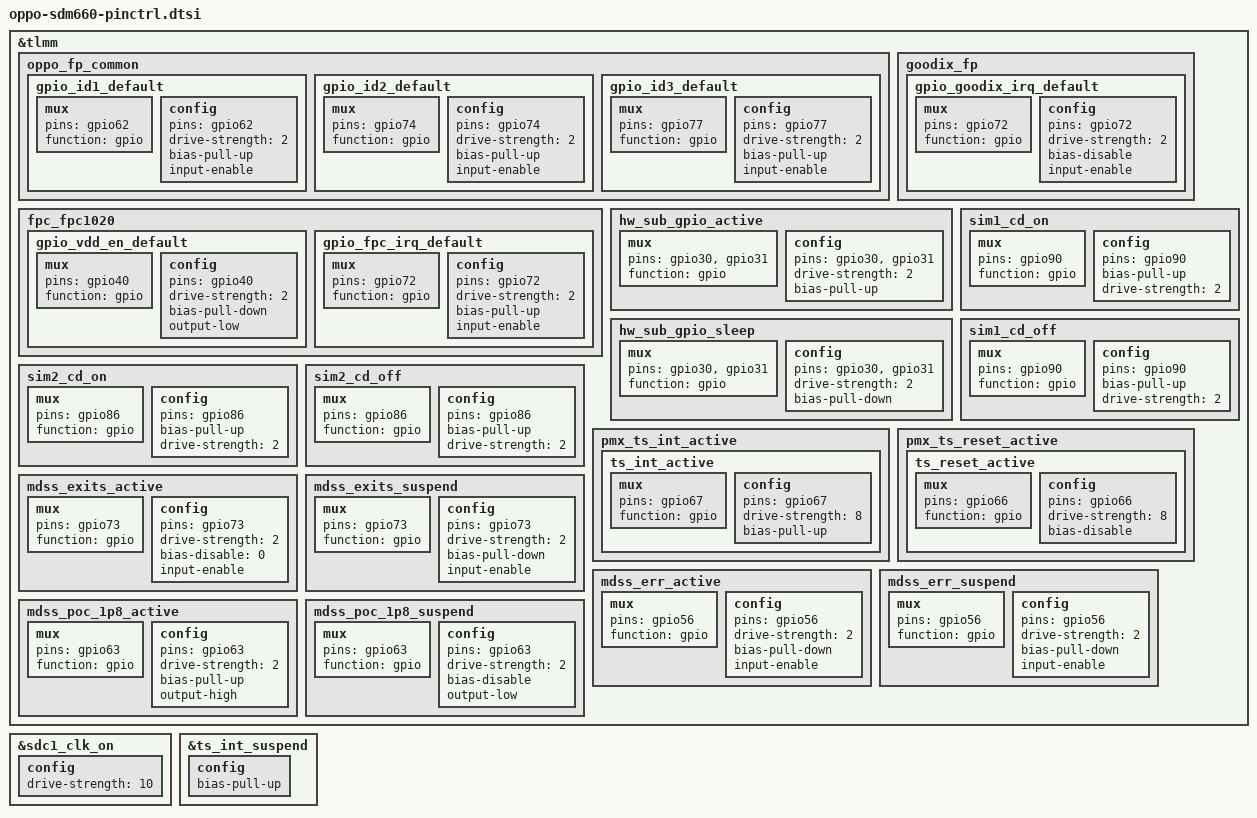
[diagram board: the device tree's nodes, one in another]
/* Copyright shits here */

&tlmm {
	oppo_fp_common {
		gpio_id1_default: gpio_id1_default {
			mux {
				pins = "gpio62";
				function = "gpio";
			};
			config {
				pins = "gpio62";
				drive-strength = <2>;
				bias-pull-up;
				input-enable;
			};
		};

		gpio_id2_default: gpio_id2_default {
			mux {
				pins = "gpio74";
				function = "gpio";
			};
			config {
				pins = "gpio74";
				drive-strength = <2>;
				bias-pull-up;
				input-enable;
			};
		};

		gpio_id3_default: gpio_id3_default {
			mux {
				pins = "gpio77";
				function = "gpio";
			};
			config {
				pins = "gpio77";
				drive-strength = <2>;
				bias-pull-up;
				input-enable;
			};
		};
	};

	fpc_fpc1020 {
		gpio_vdd_en_default: gpio_vdd_en_default {
			mux {
				pins = "gpio40";
				function = "gpio";
			};
			config {
				pins = "gpio40";
				drive-strength = <2>;
				bias-pull-down;
				output-low;
			};
		};

		gpio_fpc_irq_default: gpio_fpc_irq_default {
			mux {
				pins = "gpio72";
				function = "gpio";
			};
			config {
				pins = "gpio72";
				drive-strength = <2>;
				bias-pull-up;
				input-enable;
			};
		};
	};

	goodix_fp {
		gpio_goodix_irq_default: gpio_goodix_irq_default {
			mux {
				pins = "gpio72";
				function = "gpio";
			};
			config {
				pins = "gpio72";
				drive-strength = <2>;
				bias-disable;
				input-enable;
			};
		};
	};

	/* active state */
	hw_sub_gpio_active: hw_sub_gpio_active {
		mux {
			pins = "gpio30", "gpio31";
			function = "gpio";
		};
		config {
			pins = "gpio30", "gpio31";
			drive-strength = <2>; /* 2 MA */
			bias-pull-up;
		};
	};

	/* sleep state */
	hw_sub_gpio_sleep: hw_sub_gpio_sleep {
		mux {
			pins = "gpio30", "gpio31";
			function = "gpio";
		};
		config {
			pins = "gpio30", "gpio31";
			drive-strength = <2>; /* 2 MA */
			bias-pull-down; /* PULL DOWN */
		};
	};

	sim1_cd_on: sim1_cd_on {
		mux {
			pins = "gpio90";
			function = "gpio";
		};
		config {
			pins = "gpio90";
			bias-pull-up; /* pull up */
			drive-strength = <2>; /* 2 MA */
		};
	};

	sim1_cd_off: sim1_cd_off {
		mux {
			pins = "gpio90";
			function = "gpio";
		};
		config {
			pins = "gpio90";
			bias-pull-up; /* pull up */
			drive-strength = <2>; /* 2 MA */
		};
	};
	
	sim2_cd_on: sim2_cd_on {
		mux {
			pins = "gpio86";
			function = "gpio";
		};
		config {
			pins = "gpio86";
			bias-pull-up; /* pull up */
			drive-strength = <2>; /* 2 MA */
		};
	};

	sim2_cd_off: sim2_cd_off {
		mux {
			pins = "gpio86";
			function = "gpio";
		};
		config {
			pins = "gpio86";
			bias-pull-up; /* pull up */
			drive-strength = <2>; /* 2 MA */
		};
	};

	pmx_ts_int_active {
		ts_int_active: ts_int_active {
			mux {
				pins = "gpio67";
				function = "gpio";
			};
			config {
				pins = "gpio67";
				drive-strength = <8>;
				bias-pull-up;
			};
		};
	};

	pmx_ts_reset_active {
		ts_reset_active: ts_reset_active {
			mux {
				pins = "gpio66";
				function = "gpio";
			};
			config {
				pins = "gpio66";
				drive-strength = <8>;
				bias-disable;
			};
		};
	};

	mdss_exits_active: mdss_exits_active {
		mux {
			pins = "gpio73";
			function = "gpio";
		};
		config {
			pins = "gpio73";
			drive-strength = <2>; /* 2 mA */
			bias-disable = <0>; /* no pull */
			input-enable;
		};
	};

	mdss_exits_suspend: mdss_exits_suspend {
		mux {
			pins = "gpio73";
			function = "gpio";
		};
		config {
			pins = "gpio73";
			drive-strength = <2>; /* 2 mA */
			bias-pull-down; /* pull down */
			input-enable;
		};
	};

	mdss_err_active: mdss_err_active {
		mux {
			pins = "gpio56";
			function = "gpio";
		};
		config {
			pins = "gpio56";
			drive-strength = <2>; /* 2 mA */
			bias-pull-down; /* pull down*/
			input-enable;
		};
	};

	mdss_err_suspend: mdss_err_suspend {
		mux {
			pins = "gpio56";
			function = "gpio";
		};
		config {
			pins = "gpio56";
			drive-strength = <2>; /* 2 mA */
			bias-pull-down; /* pull down */
			input-enable;
		};
	};

	mdss_poc_1p8_active: mdss_poc_1p8_active {
		mux {
			pins = "gpio63";
			function = "gpio";
		};
		config {
			pins = "gpio63";
			drive-strength = <2>;
			bias-pull-up;
			output-high;
		};
	};

	mdss_poc_1p8_suspend: mdss_poc_1p8_suspend {
		mux {
			pins = "gpio63";
			function = "gpio";
		};
		config {
			pins = "gpio63";
			drive-strength = <2>;
			bias-disable;
			output-low;
		};
	};
};

&sdc1_clk_on {
	config {
		drive-strength = <10>; /* 10 MA */
	};
};

/* temp remove
&spi_6_active {
	mux {
		pins = "gpio52", gpio22", "gpio23";
	};
	config {
		pins = "gpio52", gpio22", "gpio23";
	};
};

&spi_6_sleep {
	mux {
		pins = "gpio52", gpio22", "gpio23";
	};
	config {
		pins = "gpio52", gpio22", "gpio23";
	};
};
*/

&ts_int_suspend {
	config {
		/delete-property/ bias-disable;
		bias-pull-up;
	};
};
